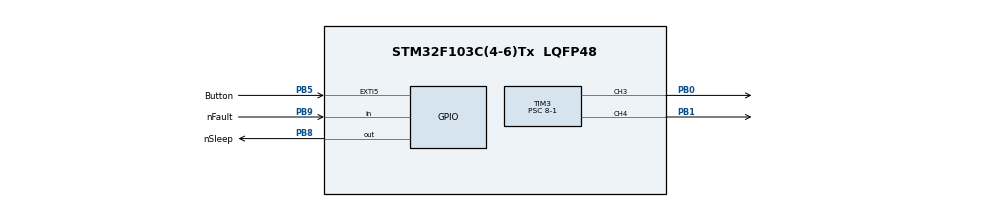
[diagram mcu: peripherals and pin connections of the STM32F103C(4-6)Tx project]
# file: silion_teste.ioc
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Mcu.Family=STM32F1
Mcu.Name=STM32F103C(4-6)Tx
Mcu.Package=LQFP48
NVIC.EXTI9_5_IRQn=true\:0\:0\:false\:false\:true\:true\:true\:true
NVIC.PriorityGroup=NVIC_PRIORITYGROUP_4
NVIC.TIM2_IRQn=true\:0\:0\:false\:false\:true\:true\:true\:true
PB0.Signal=S_TIM3_CH3
PB1.Signal=S_TIM3_CH4
PB5.GPIO_Label=Button
PB5.GPIO_ModeDefaultEXTI=GPIO_MODE_IT_FALLING
PB5.Signal=GPXTI5
PB6.Signal=I2C1_SCL
PB7.Signal=I2C1_SDA
PB8.GPIO_Label=nSleep
PB8.Signal=GPIO_Output
PB9.GPIO_Label=nFault
PB9.Signal=GPIO_Input
ProjectManager.HeapSize=0x200
ProjectManager.StackSize=0x400
ProjectManager.TargetToolchain=STM32CubeIDE
RCC.APB1Freq_Value=8000000
RCC.APB2Freq_Value=8000000
SH.S_TIM3_CH3.0=TIM3_CH3,PWM Generation3 CH3
SH.S_TIM3_CH4.0=TIM3_CH4,PWM Generation4 CH4
TIM2.Period=1000-1
TIM2.Prescaler=8000-1
TIM3.Channel-PWM\ Generation3\ CH3=TIM_CHANNEL_3
TIM3.Channel-PWM\ Generation4\ CH4=TIM_CHANNEL_4
TIM3.Period=1000-1
TIM3.Prescaler=8-1
VP_SYS_VS_ND.Mode=No_Debug
VP_TIM2_VS_ClockSourceINT.Mode=Internal
board=custom

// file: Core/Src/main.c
/* USER CODE BEGIN Header */
/**
  ******************************************************************************
  * @file           : main.c
  * @brief          : Main program body
  ******************************************************************************
  * @attention
  *
  * Copyright (c) 2024 STMicroelectronics.
  * All rights reserved.
  *
  * This software is licensed under terms that can be found in the LICENSE file
  * in the root directory of this software component.
  * If no LICENSE file comes with this software, it is provided AS-IS.
  *
  ******************************************************************************
  */
/* USER CODE END Header */
#include "main.h"

TIM_HandleTypeDef htim2;
TIM_HandleTypeDef htim3;

void SystemClock_Config(void);
static void MX_GPIO_Init(void);
static void MX_TIM3_Init(void);
static void MX_TIM2_Init(void);

/* USER CODE BEGIN 0 */
int sec = 0;
/* USER CODE END 0 */

int main(void)
{

  /* MCU Configuration--------------------------------------------------------*/

  /* Reset of all peripherals, Initializes the Flash interface and the Systick. */
  HAL_Init();

  /* Configure the system clock */
  SystemClock_Config();

  /* Initialize all configured peripherals */
  MX_GPIO_Init();
  MX_TIM3_Init();
  MX_TIM2_Init();

  /* Infinite loop */
  while (1)
  {

  }
}

void HAL_GPIO_EXTI_Callback(uint16_t GPIO_Pin)
{
  /* Prevent unused argument(s) compilation warning */
  if(GPIO_Pin == GPIO_PIN_5){
	  HAL_TIM_PWM_Start(&htim3, TIM_CHANNEL_3);
	  HAL_TIM_Base_Start_IT(&htim2);
  }
  /* NOTE: This function Should not be modified, when the callback is needed,
           the HAL_GPIO_EXTI_Callback could be implemented in the user file
   */
}

void HAL_TIM_PeriodElapsedCallback(TIM_HandleTypeDef *htim)
{
  /* Prevent unused argument(s) compilation warning */
  if(htim == &htim2){
	  ++sec;
	  if(sec == 10){
		  HAL_TIM_PWM_Stop(&htim3, TIM_CHANNEL_3);
		  HAL_TIM_Base_Stop_IT(&htim2);
	  }

  }

  /* NOTE : This function should not be modified, when the callback is needed,
            the HAL_TIM_PeriodElapsedCallback could be implemented in the user file
   */
}

void SystemClock_Config(void)
{
  RCC_OscInitTypeDef RCC_OscInitStruct = {0};
  RCC_ClkInitTypeDef RCC_ClkInitStruct = {0};

  /** Initializes the RCC Oscillators according to the specified parameters
  * in the RCC_OscInitTypeDef structure.
  */
  RCC_OscInitStruct.OscillatorType = RCC_OSCILLATORTYPE_HSI;
  RCC_OscInitStruct.HSIState = RCC_HSI_ON;
  RCC_OscInitStruct.HSICalibrationValue = RCC_HSICALIBRATION_DEFAULT;
  RCC_OscInitStruct.PLL.PLLState = RCC_PLL_NONE;
  if (HAL_RCC_OscConfig(&RCC_OscInitStruct) != HAL_OK)
  {
    Error_Handler();
  }

  /** Initializes the CPU, AHB and APB buses clocks
  */
  RCC_ClkInitStruct.ClockType = RCC_CLOCKTYPE_HCLK|RCC_CLOCKTYPE_SYSCLK
                              |RCC_CLOCKTYPE_PCLK1|RCC_CLOCKTYPE_PCLK2;
  RCC_ClkInitStruct.SYSCLKSource = RCC_SYSCLKSOURCE_HSI;
  RCC_ClkInitStruct.AHBCLKDivider = RCC_SYSCLK_DIV1;
  RCC_ClkInitStruct.APB1CLKDivider = RCC_HCLK_DIV1;
  RCC_ClkInitStruct.APB2CLKDivider = RCC_HCLK_DIV1;

  if (HAL_RCC_ClockConfig(&RCC_ClkInitStruct, FLASH_LATENCY_0) != HAL_OK)
  {
    Error_Handler();
  }
}

static void MX_TIM2_Init(void)
{

  TIM_ClockConfigTypeDef sClockSourceConfig = {0};
  TIM_MasterConfigTypeDef sMasterConfig = {0};

  htim2.Instance = TIM2;
  htim2.Init.Prescaler = 8000-1;
  htim2.Init.CounterMode = TIM_COUNTERMODE_UP;
  htim2.Init.Period = 1000-1;
  htim2.Init.ClockDivision = TIM_CLOCKDIVISION_DIV1;
  htim2.Init.AutoReloadPreload = TIM_AUTORELOAD_PRELOAD_DISABLE;
  if (HAL_TIM_Base_Init(&htim2) != HAL_OK)
  {
    Error_Handler();
  }
  sClockSourceConfig.ClockSource = TIM_CLOCKSOURCE_INTERNAL;
  if (HAL_TIM_ConfigClockSource(&htim2, &sClockSourceConfig) != HAL_OK)
  {
    Error_Handler();
  }
  sMasterConfig.MasterOutputTrigger = TIM_TRGO_RESET;
  sMasterConfig.MasterSlaveMode = TIM_MASTERSLAVEMODE_DISABLE;
  if (HAL_TIMEx_MasterConfigSynchronization(&htim2, &sMasterConfig) != HAL_OK)
  {
    Error_Handler();
  }

}

static void MX_TIM3_Init(void)
{

  TIM_MasterConfigTypeDef sMasterConfig = {0};
  TIM_OC_InitTypeDef sConfigOC = {0};

  htim3.Instance = TIM3;
  htim3.Init.Prescaler = 8-1;
  htim3.Init.CounterMode = TIM_COUNTERMODE_UP;
  htim3.Init.Period = 1000-1;
  htim3.Init.ClockDivision = TIM_CLOCKDIVISION_DIV1;
  htim3.Init.AutoReloadPreload = TIM_AUTORELOAD_PRELOAD_DISABLE;
  if (HAL_TIM_PWM_Init(&htim3) != HAL_OK)
  {
    Error_Handler();
  }
  sMasterConfig.MasterOutputTrigger = TIM_TRGO_RESET;
  sMasterConfig.MasterSlaveMode = TIM_MASTERSLAVEMODE_DISABLE;
  if (HAL_TIMEx_MasterConfigSynchronization(&htim3, &sMasterConfig) != HAL_OK)
  {
    Error_Handler();
  }
  sConfigOC.OCMode = TIM_OCMODE_PWM1;
  sConfigOC.Pulse = 0;
  sConfigOC.OCPolarity = TIM_OCPOLARITY_HIGH;
  sConfigOC.OCFastMode = TIM_OCFAST_DISABLE;
  if (HAL_TIM_PWM_ConfigChannel(&htim3, &sConfigOC, TIM_CHANNEL_3) != HAL_OK)
  {
    Error_Handler();
  }
  if (HAL_TIM_PWM_ConfigChannel(&htim3, &sConfigOC, TIM_CHANNEL_4) != HAL_OK)
  {
    Error_Handler();
  }
  HAL_TIM_MspPostInit(&htim3);

}

static void MX_GPIO_Init(void)
{
  GPIO_InitTypeDef GPIO_InitStruct = {0};

  /* GPIO Ports Clock Enable */
  __HAL_RCC_GPIOB_CLK_ENABLE();

  /*Configure GPIO pin Output Level */
  HAL_GPIO_WritePin(nSleep_GPIO_Port, nSleep_Pin, GPIO_PIN_RESET);

  /*Configure GPIO pin : Button_Pin */
  GPIO_InitStruct.Pin = Button_Pin;
  GPIO_InitStruct.Mode = GPIO_MODE_IT_FALLING;
  GPIO_InitStruct.Pull = GPIO_NOPULL;
  HAL_GPIO_Init(Button_GPIO_Port, &GPIO_InitStruct);

  /*Configure GPIO pins : PB6 PB7 */
  GPIO_InitStruct.Pin = GPIO_PIN_6|GPIO_PIN_7;
  GPIO_InitStruct.Mode = GPIO_MODE_AF_OD;
  GPIO_InitStruct.Pull = GPIO_NOPULL;
  GPIO_InitStruct.Speed = GPIO_SPEED_FREQ_HIGH;
  HAL_GPIO_Init(GPIOB, &GPIO_InitStruct);

  /*Configure GPIO pin : nSleep_Pin */
  GPIO_InitStruct.Pin = nSleep_Pin;
  GPIO_InitStruct.Mode = GPIO_MODE_OUTPUT_PP;
  GPIO_InitStruct.Pull = GPIO_NOPULL;
  GPIO_InitStruct.Speed = GPIO_SPEED_FREQ_LOW;
  HAL_GPIO_Init(nSleep_GPIO_Port, &GPIO_InitStruct);

  /*Configure GPIO pin : nFault_Pin */
  GPIO_InitStruct.Pin = nFault_Pin;
  GPIO_InitStruct.Mode = GPIO_MODE_INPUT;
  GPIO_InitStruct.Pull = GPIO_NOPULL;
  HAL_GPIO_Init(nFault_GPIO_Port, &GPIO_InitStruct);

  /* EXTI interrupt init*/
  HAL_NVIC_SetPriority(EXTI9_5_IRQn, 0, 0);
  HAL_NVIC_EnableIRQ(EXTI9_5_IRQn);

}

void Error_Handler(void)
{
  __disable_irq();
  while (1)
  {
  }
}
